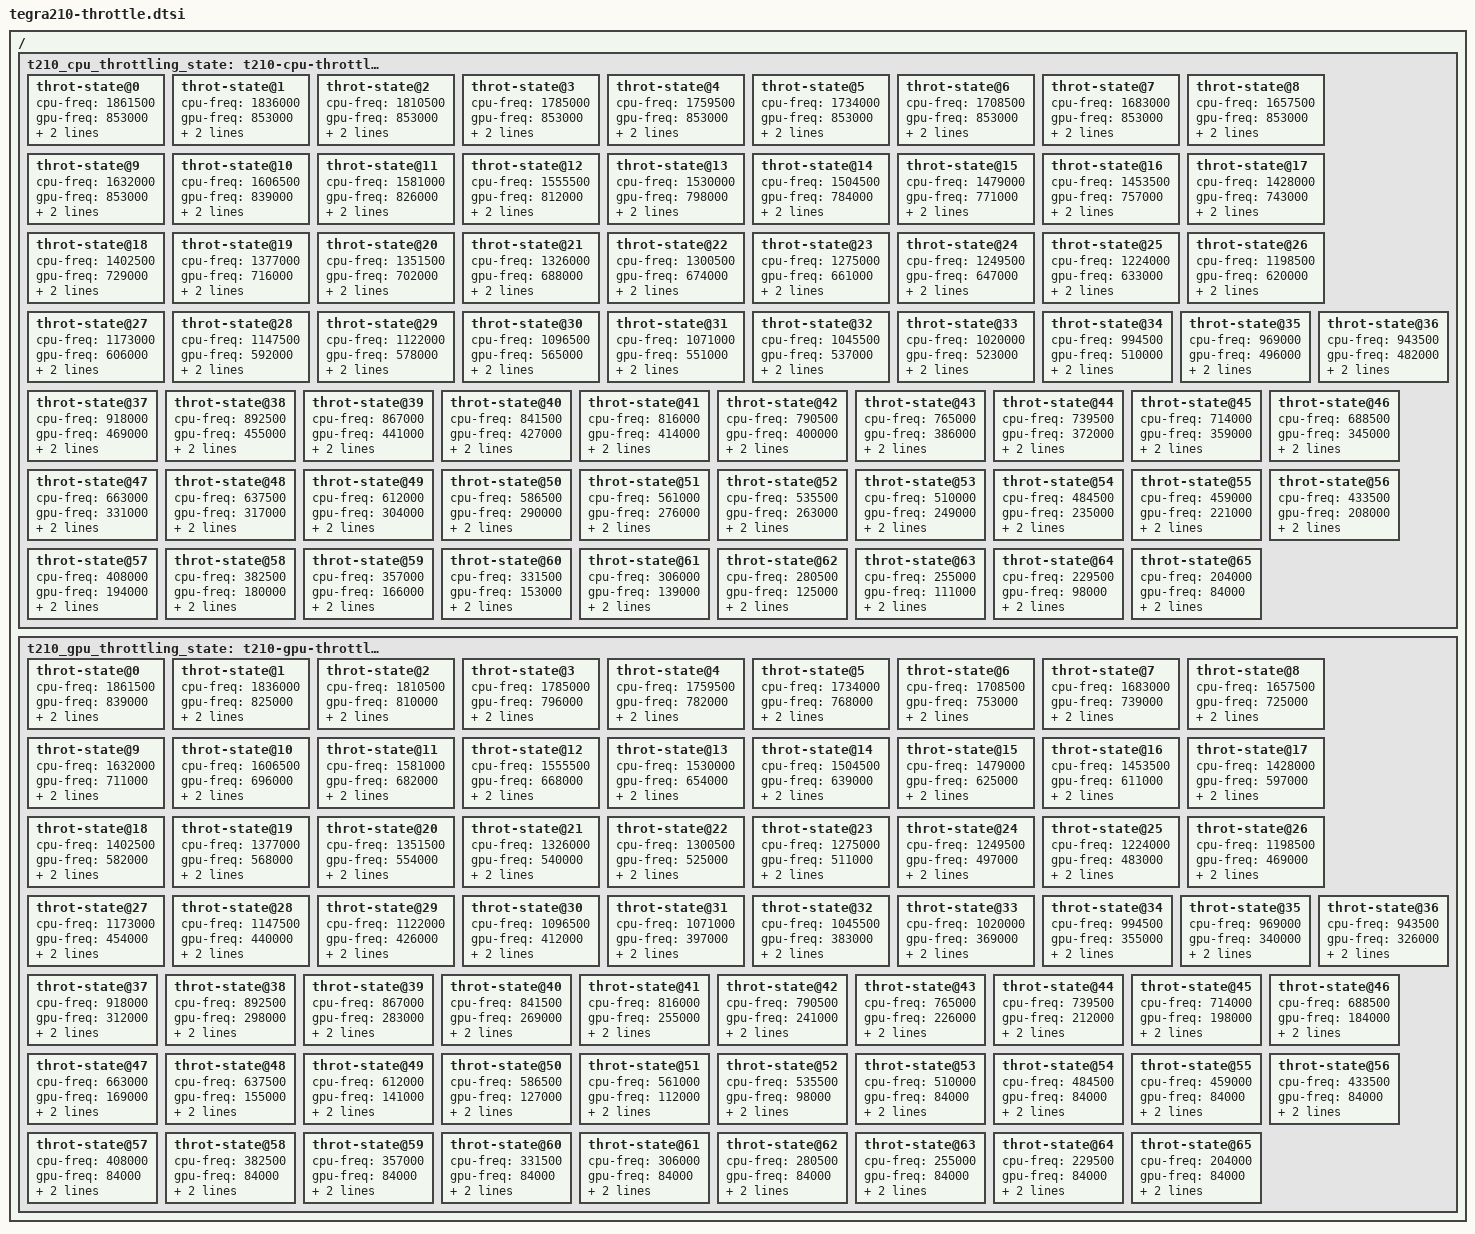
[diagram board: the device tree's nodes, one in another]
/ {
	t210_cpu_throttling_state: t210-cpu-throttling-state {
		throt-state@0 {
			cpu-freq = <1861500>;
			gpu-freq = <853000>;
			c3bus-freq = <512000>;
			sclk-freq = <384000>;
		};
		throt-state@1 {
			cpu-freq = <1836000>;
			gpu-freq = <853000>;
			c3bus-freq = <512000>;
			sclk-freq = <384000>;
		};
		throt-state@2 {
			cpu-freq = <1810500>;
			gpu-freq = <853000>;
			c3bus-freq = <512000>;
			sclk-freq = <384000>;
		};
		throt-state@3 {
			cpu-freq = <1785000>;
			gpu-freq = <853000>;
			c3bus-freq = <512000>;
			sclk-freq = <384000>;
		};
		throt-state@4 {
			cpu-freq = <1759500>;
			gpu-freq = <853000>;
			c3bus-freq = <512000>;
			sclk-freq = <384000>;
		};
		throt-state@5 {
			cpu-freq = <1734000>;
			gpu-freq = <853000>;
			c3bus-freq = <512000>;
			sclk-freq = <384000>;
		};
		throt-state@6 {
			cpu-freq = <1708500>;
			gpu-freq = <853000>;
			c3bus-freq = <512000>;
			sclk-freq = <384000>;
		};
		throt-state@7 {
			cpu-freq = <1683000>;
			gpu-freq = <853000>;
			c3bus-freq = <512000>;
			sclk-freq = <384000>;
		};
		throt-state@8 {
			cpu-freq = <1657500>;
			gpu-freq = <853000>;
			c3bus-freq = <512000>;
			sclk-freq = <384000>;
		};
		throt-state@9 {
			cpu-freq = <1632000>;
			gpu-freq = <853000>;
			c3bus-freq = <512000>;
			sclk-freq = <384000>;
		};
		throt-state@10 {
			cpu-freq = <1606500>;
			gpu-freq = <839000>;
			c3bus-freq = <512000>;
			sclk-freq = <384000>;
		};
		throt-state@11 {
			cpu-freq = <1581000>;
			gpu-freq = <826000>;
			c3bus-freq = <512000>;
			sclk-freq = <384000>;
		};
		throt-state@12 {
			cpu-freq = <1555500>;
			gpu-freq = <812000>;
			c3bus-freq = <512000>;
			sclk-freq = <384000>;
		};
		throt-state@13 {
			cpu-freq = <1530000>;
			gpu-freq = <798000>;
			c3bus-freq = <512000>;
			sclk-freq = <384000>;
		};
		throt-state@14 {
			cpu-freq = <1504500>;
			gpu-freq = <784000>;
			c3bus-freq = <512000>;
			sclk-freq = <384000>;
		};
		throt-state@15 {
			cpu-freq = <1479000>;
			gpu-freq = <771000>;
			c3bus-freq = <512000>;
			sclk-freq = <384000>;
		};
		throt-state@16 {
			cpu-freq = <1453500>;
			gpu-freq = <757000>;
			c3bus-freq = <512000>;
			sclk-freq = <384000>;
		};
		throt-state@17 {
			cpu-freq = <1428000>;
			gpu-freq = <743000>;
			c3bus-freq = <512000>;
			sclk-freq = <384000>;
		};
		throt-state@18 {
			cpu-freq = <1402500>;
			gpu-freq = <729000>;
			c3bus-freq = <512000>;
			sclk-freq = <384000>;
		};
		throt-state@19 {
			cpu-freq = <1377000>;
			gpu-freq = <716000>;
			c3bus-freq = <512000>;
			sclk-freq = <384000>;
		};
		throt-state@20 {
			cpu-freq = <1351500>;
			gpu-freq = <702000>;
			c3bus-freq = <512000>;
			sclk-freq = <384000>;
		};
		throt-state@21 {
			cpu-freq = <1326000>;
			gpu-freq = <688000>;
			c3bus-freq = <512000>;
			sclk-freq = <384000>;
		};
		throt-state@22 {
			cpu-freq = <1300500>;
			gpu-freq = <674000>;
			c3bus-freq = <512000>;
			sclk-freq = <384000>;
		};
		throt-state@23 {
			cpu-freq = <1275000>;
			gpu-freq = <661000>;
			c3bus-freq = <512000>;
			sclk-freq = <384000>;
		};
		throt-state@24 {
			cpu-freq = <1249500>;
			gpu-freq = <647000>;
			c3bus-freq = <512000>;
			sclk-freq = <384000>;
		};
		throt-state@25 {
			cpu-freq = <1224000>;
			gpu-freq = <633000>;
			c3bus-freq = <512000>;
			sclk-freq = <384000>;
		};
		throt-state@26 {
			cpu-freq = <1198500>;
			gpu-freq = <620000>;
			c3bus-freq = <512000>;
			sclk-freq = <384000>;
		};
		throt-state@27 {
			cpu-freq = <1173000>;
			gpu-freq = <606000>;
			c3bus-freq = <512000>;
			sclk-freq = <384000>;
		};
		throt-state@28 {
			cpu-freq = <1147500>;
			gpu-freq = <592000>;
			c3bus-freq = <512000>;
			sclk-freq = <384000>;
		};
		throt-state@29 {
			cpu-freq = <1122000>;
			gpu-freq = <578000>;
			c3bus-freq = <512000>;
			sclk-freq = <384000>;
		};
		throt-state@30 {
			cpu-freq = <1096500>;
			gpu-freq = <565000>;
			c3bus-freq = <512000>;
			sclk-freq = <384000>;
		};
		throt-state@31 {
			cpu-freq = <1071000>;
			gpu-freq = <551000>;
			c3bus-freq = <512000>;
			sclk-freq = <384000>;
		};
		throt-state@32 {
			cpu-freq = <1045500>;
			gpu-freq = <537000>;
			c3bus-freq = <512000>;
			sclk-freq = <384000>;
		};
		throt-state@33 {
			cpu-freq = <1020000>;
			gpu-freq = <523000>;
			c3bus-freq = <512000>;
			sclk-freq = <384000>;
		};
		throt-state@34 {
			cpu-freq = <994500>;
			gpu-freq = <510000>;
			c3bus-freq = <512000>;
			sclk-freq = <384000>;
		};
		throt-state@35 {
			cpu-freq = <969000>;
			gpu-freq = <496000>;
			c3bus-freq = <486400>;
			sclk-freq = <384000>;
		};
		throt-state@36 {
			cpu-freq = <943500>;
			gpu-freq = <482000>;
			c3bus-freq = <486400>;
			sclk-freq = <384000>;
		};
		throt-state@37 {
			cpu-freq = <918000>;
			gpu-freq = <469000>;
			c3bus-freq = <486400>;
			sclk-freq = <384000>;
		};
		throt-state@38 {
			cpu-freq = <892500>;
			gpu-freq = <455000>;
			c3bus-freq = <486400>;
			sclk-freq = <384000>;
		};
		throt-state@39 {
			cpu-freq = <867000>;
			gpu-freq = <441000>;
			c3bus-freq = <486400>;
			sclk-freq = <384000>;
		};
		throt-state@40 {
			cpu-freq = <841500>;
			gpu-freq = <427000>;
			c3bus-freq = <486400>;
			sclk-freq = <384000>;
		};
		throt-state@41 {
			cpu-freq = <816000>;
			gpu-freq = <414000>;
			c3bus-freq = <486400>;
			sclk-freq = <384000>;
		};
		throt-state@42 {
			cpu-freq = <790500>;
			gpu-freq = <400000>;
			c3bus-freq = <486400>;
			sclk-freq = <384000>;
		};
		throt-state@43 {
			cpu-freq = <765000>;
			gpu-freq = <386000>;
			c3bus-freq = <486400>;
			sclk-freq = <384000>;
		};
		throt-state@44 {
			cpu-freq = <739500>;
			gpu-freq = <372000>;
			c3bus-freq = <473600>;
			sclk-freq = <384000>;
		};
		throt-state@45 {
			cpu-freq = <714000>;
			gpu-freq = <359000>;
			c3bus-freq = <473600>;
			sclk-freq = <384000>;
		};
		throt-state@46 {
			cpu-freq = <688500>;
			gpu-freq = <345000>;
			c3bus-freq = <473600>;
			sclk-freq = <384000>;
		};
		throt-state@47 {
			cpu-freq = <663000>;
			gpu-freq = <331000>;
			c3bus-freq = <473600>;
			sclk-freq = <384000>;
		};
		throt-state@48 {
			cpu-freq = <637500>;
			gpu-freq = <317000>;
			c3bus-freq = <473600>;
			sclk-freq = <384000>;
		};
		throt-state@49 {
			cpu-freq = <612000>;
			gpu-freq = <304000>;
			c3bus-freq = <473600>;
			sclk-freq = <384000>;
		};
		throt-state@50 {
			cpu-freq = <586500>;
			gpu-freq = <290000>;
			c3bus-freq = <473600>;
			sclk-freq = <384000>;
		};
		throt-state@51 {
			cpu-freq = <561000>;
			gpu-freq = <276000>;
			c3bus-freq = <435200>;
			sclk-freq = <384000>;
		};
		throt-state@52 {
			cpu-freq = <535500>;
			gpu-freq = <263000>;
			c3bus-freq = <435200>;
			sclk-freq = <384000>;
		};
		throt-state@53 {
			cpu-freq = <510000>;
			gpu-freq = <249000>;
			c3bus-freq = <435200>;
			sclk-freq = <384000>;
		};
		throt-state@54 {
			cpu-freq = <484500>;
			gpu-freq = <235000>;
			c3bus-freq = <435200>;
			sclk-freq = <384000>;
		};
		throt-state@55 {
			cpu-freq = <459000>;
			gpu-freq = <221000>;
			c3bus-freq = <435200>;
			sclk-freq = <384000>;
		};
		throt-state@56 {
			cpu-freq = <433500>;
			gpu-freq = <208000>;
			c3bus-freq = <435200>;
			sclk-freq = <384000>;
		};
		throt-state@57 {
			cpu-freq = <408000>;
			gpu-freq = <194000>;
			c3bus-freq = <396800>;
			sclk-freq = <384000>;
		};
		throt-state@58 {
			cpu-freq = <382500>;
			gpu-freq = <180000>;
			c3bus-freq = <396800>;
			sclk-freq = <384000>;
		};
		throt-state@59 {
			cpu-freq = <357000>;
			gpu-freq = <166000>;
			c3bus-freq = <396800>;
			sclk-freq = <384000>;
		};
		throt-state@60 {
			cpu-freq = <331500>;
			gpu-freq = <153000>;
			c3bus-freq = <396800>;
			sclk-freq = <384000>;
		};
		throt-state@61 {
			cpu-freq = <306000>;
			gpu-freq = <139000>;
			c3bus-freq = <396800>;
			sclk-freq = <384000>;
		};
		throt-state@62 {
			cpu-freq = <280500>;
			gpu-freq = <125000>;
			c3bus-freq = <396800>;
			sclk-freq = <384000>;
		};
		throt-state@63 {
			cpu-freq = <255000>;
			gpu-freq = <111000>;
			c3bus-freq = <396800>;
			sclk-freq = <384000>;
		};
		throt-state@64 {
			cpu-freq = <229500>;
			gpu-freq = <98000>;
			c3bus-freq = <396800>;
			sclk-freq = <384000>;
		};
		throt-state@65 {
			cpu-freq = <204000>;
			gpu-freq = <84000>;
			c3bus-freq = <396800>;
			sclk-freq = <384000>;
		};
	};

	t210_gpu_throttling_state: t210-gpu-throttling-state {
		throt-state@0 {
			cpu-freq = <1861500>;
			gpu-freq = <839000>;
			c3bus-freq = <512000>;
			sclk-freq = <384000>;
		};
		throt-state@1 {
			cpu-freq = <1836000>;
			gpu-freq = <825000>;
			c3bus-freq = <512000>;
			sclk-freq = <384000>;
		};
		throt-state@2 {
			cpu-freq = <1810500>;
			gpu-freq = <810000>;
			c3bus-freq = <512000>;
			sclk-freq = <384000>;
		};
		throt-state@3 {
			cpu-freq = <1785000>;
			gpu-freq = <796000>;
			c3bus-freq = <512000>;
			sclk-freq = <384000>;
		};
		throt-state@4 {
			cpu-freq = <1759500>;
			gpu-freq = <782000>;
			c3bus-freq = <512000>;
			sclk-freq = <384000>;
		};
		throt-state@5 {
			cpu-freq = <1734000>;
			gpu-freq = <768000>;
			c3bus-freq = <512000>;
			sclk-freq = <384000>;
		};
		throt-state@6 {
			cpu-freq = <1708500>;
			gpu-freq = <753000>;
			c3bus-freq = <512000>;
			sclk-freq = <384000>;
		};
		throt-state@7 {
			cpu-freq = <1683000>;
			gpu-freq = <739000>;
			c3bus-freq = <512000>;
			sclk-freq = <384000>;
		};
		throt-state@8 {
			cpu-freq = <1657500>;
			gpu-freq = <725000>;
			c3bus-freq = <512000>;
			sclk-freq = <384000>;
		};
		throt-state@9 {
			cpu-freq = <1632000>;
			gpu-freq = <711000>;
			c3bus-freq = <512000>;
			sclk-freq = <384000>;
		};
		throt-state@10 {
			cpu-freq = <1606500>;
			gpu-freq = <696000>;
			c3bus-freq = <512000>;
			sclk-freq = <384000>;
		};
		throt-state@11 {
			cpu-freq = <1581000>;
			gpu-freq = <682000>;
			c3bus-freq = <512000>;
			sclk-freq = <384000>;
		};
		throt-state@12 {
			cpu-freq = <1555500>;
			gpu-freq = <668000>;
			c3bus-freq = <512000>;
			sclk-freq = <384000>;
		};
		throt-state@13 {
			cpu-freq = <1530000>;
			gpu-freq = <654000>;
			c3bus-freq = <512000>;
			sclk-freq = <384000>;
		};
		throt-state@14 {
			cpu-freq = <1504500>;
			gpu-freq = <639000>;
			c3bus-freq = <512000>;
			sclk-freq = <384000>;
		};
		throt-state@15 {
			cpu-freq = <1479000>;
			gpu-freq = <625000>;
			c3bus-freq = <512000>;
			sclk-freq = <384000>;
		};
		throt-state@16 {
			cpu-freq = <1453500>;
			gpu-freq = <611000>;
			c3bus-freq = <512000>;
			sclk-freq = <384000>;
		};
		throt-state@17 {
			cpu-freq = <1428000>;
			gpu-freq = <597000>;
			c3bus-freq = <512000>;
			sclk-freq = <384000>;
		};
		throt-state@18 {
			cpu-freq = <1402500>;
			gpu-freq = <582000>;
			c3bus-freq = <512000>;
			sclk-freq = <384000>;
		};
		throt-state@19 {
			cpu-freq = <1377000>;
			gpu-freq = <568000>;
			c3bus-freq = <512000>;
			sclk-freq = <384000>;
		};
		throt-state@20 {
			cpu-freq = <1351500>;
			gpu-freq = <554000>;
			c3bus-freq = <512000>;
			sclk-freq = <384000>;
		};
		throt-state@21 {
			cpu-freq = <1326000>;
			gpu-freq = <540000>;
			c3bus-freq = <512000>;
			sclk-freq = <384000>;
		};
		throt-state@22 {
			cpu-freq = <1300500>;
			gpu-freq = <525000>;
			c3bus-freq = <512000>;
			sclk-freq = <384000>;
		};
		throt-state@23 {
			cpu-freq = <1275000>;
			gpu-freq = <511000>;
			c3bus-freq = <512000>;
			sclk-freq = <384000>;
		};
		throt-state@24 {
			cpu-freq = <1249500>;
			gpu-freq = <497000>;
			c3bus-freq = <512000>;
			sclk-freq = <384000>;
		};
		throt-state@25 {
			cpu-freq = <1224000>;
			gpu-freq = <483000>;
			c3bus-freq = <512000>;
			sclk-freq = <384000>;
		};
		throt-state@26 {
			cpu-freq = <1198500>;
			gpu-freq = <469000>;
			c3bus-freq = <512000>;
			sclk-freq = <384000>;
		};
		throt-state@27 {
			cpu-freq = <1173000>;
			gpu-freq = <454000>;
			c3bus-freq = <512000>;
			sclk-freq = <384000>;
		};
		throt-state@28 {
			cpu-freq = <1147500>;
			gpu-freq = <440000>;
			c3bus-freq = <512000>;
			sclk-freq = <384000>;
		};
		throt-state@29 {
			cpu-freq = <1122000>;
			gpu-freq = <426000>;
			c3bus-freq = <512000>;
			sclk-freq = <384000>;
		};
		throt-state@30 {
			cpu-freq = <1096500>;
			gpu-freq = <412000>;
			c3bus-freq = <512000>;
			sclk-freq = <384000>;
		};
		throt-state@31 {
			cpu-freq = <1071000>;
			gpu-freq = <397000>;
			c3bus-freq = <512000>;
			sclk-freq = <384000>;
		};
		throt-state@32 {
			cpu-freq = <1045500>;
			gpu-freq = <383000>;
			c3bus-freq = <512000>;
			sclk-freq = <384000>;
		};
		throt-state@33 {
			cpu-freq = <1020000>;
			gpu-freq = <369000>;
			c3bus-freq = <512000>;
			sclk-freq = <384000>;
		};
		throt-state@34 {
			cpu-freq = <994500>;
			gpu-freq = <355000>;
			c3bus-freq = <512000>;
			sclk-freq = <384000>;
		};
		throt-state@35 {
			cpu-freq = <969000>;
			gpu-freq = <340000>;
			c3bus-freq = <486400>;
			sclk-freq = <384000>;
		};
		throt-state@36 {
			cpu-freq = <943500>;
			gpu-freq = <326000>;
			c3bus-freq = <486400>;
			sclk-freq = <384000>;
		};
		throt-state@37 {
			cpu-freq = <918000>;
			gpu-freq = <312000>;
			c3bus-freq = <486400>;
			sclk-freq = <384000>;
		};
		throt-state@38 {
			cpu-freq = <892500>;
			gpu-freq = <298000>;
			c3bus-freq = <486400>;
			sclk-freq = <384000>;
		};
		throt-state@39 {
			cpu-freq = <867000>;
			gpu-freq = <283000>;
			c3bus-freq = <486400>;
			sclk-freq = <384000>;
		};
		throt-state@40 {
			cpu-freq = <841500>;
			gpu-freq = <269000>;
			c3bus-freq = <486400>;
			sclk-freq = <384000>;
		};
		throt-state@41 {
			cpu-freq = <816000>;
			gpu-freq = <255000>;
			c3bus-freq = <486400>;
			sclk-freq = <384000>;
		};
		throt-state@42 {
			cpu-freq = <790500>;
			gpu-freq = <241000>;
			c3bus-freq = <486400>;
			sclk-freq = <384000>;
		};
		throt-state@43 {
			cpu-freq = <765000>;
			gpu-freq = <226000>;
			c3bus-freq = <486400>;
			sclk-freq = <384000>;
		};
		throt-state@44 {
			cpu-freq = <739500>;
			gpu-freq = <212000>;
			c3bus-freq = <473600>;
			sclk-freq = <384000>;
		};
		throt-state@45 {
			cpu-freq = <714000>;
			gpu-freq = <198000>;
			c3bus-freq = <473600>;
			sclk-freq = <384000>;
		};
		throt-state@46 {
			cpu-freq = <688500>;
			gpu-freq = <184000>;
			c3bus-freq = <473600>;
			sclk-freq = <384000>;
		};
		throt-state@47 {
			cpu-freq = <663000>;
			gpu-freq = <169000>;
			c3bus-freq = <473600>;
			sclk-freq = <384000>;
		};
		throt-state@48 {
			cpu-freq = <637500>;
			gpu-freq = <155000>;
			c3bus-freq = <473600>;
			sclk-freq = <384000>;
		};
		throt-state@49 {
			cpu-freq = <612000>;
			gpu-freq = <141000>;
			c3bus-freq = <473600>;
			sclk-freq = <384000>;
		};
		throt-state@50 {
			cpu-freq = <586500>;
			gpu-freq = <127000>;
			c3bus-freq = <473600>;
			sclk-freq = <384000>;
		};
		throt-state@51 {
			cpu-freq = <561000>;
			gpu-freq = <112000>;
			c3bus-freq = <435200>;
			sclk-freq = <384000>;
		};
		throt-state@52 {
			cpu-freq = <535500>;
			gpu-freq = <98000>;
			c3bus-freq = <435200>;
			sclk-freq = <384000>;
		};
		throt-state@53 {
			cpu-freq = <510000>;
			gpu-freq = <84000>;
			c3bus-freq = <435200>;
			sclk-freq = <384000>;
		};
		throt-state@54 {
			cpu-freq = <484500>;
			gpu-freq = <84000>;
			c3bus-freq = <435200>;
			sclk-freq = <384000>;
		};
		throt-state@55 {
			cpu-freq = <459000>;
			gpu-freq = <84000>;
			c3bus-freq = <435200>;
			sclk-freq = <384000>;
		};
		throt-state@56 {
			cpu-freq = <433500>;
			gpu-freq = <84000>;
			c3bus-freq = <435200>;
			sclk-freq = <384000>;
		};
		throt-state@57 {
			cpu-freq = <408000>;
			gpu-freq = <84000>;
			c3bus-freq = <396800>;
			sclk-freq = <384000>;
		};
		throt-state@58 {
			cpu-freq = <382500>;
			gpu-freq = <84000>;
			c3bus-freq = <396800>;
			sclk-freq = <384000>;
		};
		throt-state@59 {
			cpu-freq = <357000>;
			gpu-freq = <84000>;
			c3bus-freq = <396800>;
			sclk-freq = <384000>;
		};
		throt-state@60 {
			cpu-freq = <331500>;
			gpu-freq = <84000>;
			c3bus-freq = <396800>;
			sclk-freq = <384000>;
		};
		throt-state@61 {
			cpu-freq = <306000>;
			gpu-freq = <84000>;
			c3bus-freq = <396800>;
			sclk-freq = <384000>;
		};
		throt-state@62 {
			cpu-freq = <280500>;
			gpu-freq = <84000>;
			c3bus-freq = <396800>;
			sclk-freq = <384000>;
		};
		throt-state@63 {
			cpu-freq = <255000>;
			gpu-freq = <84000>;
			c3bus-freq = <396800>;
			sclk-freq = <384000>;
		};
		throt-state@64 {
			cpu-freq = <229500>;
			gpu-freq = <84000>;
			c3bus-freq = <396800>;
			sclk-freq = <384000>;
		};
		throt-state@65 {
			cpu-freq = <204000>;
			gpu-freq = <84000>;
			c3bus-freq = <396800>;
			sclk-freq = <384000>;
		};
	};
};
